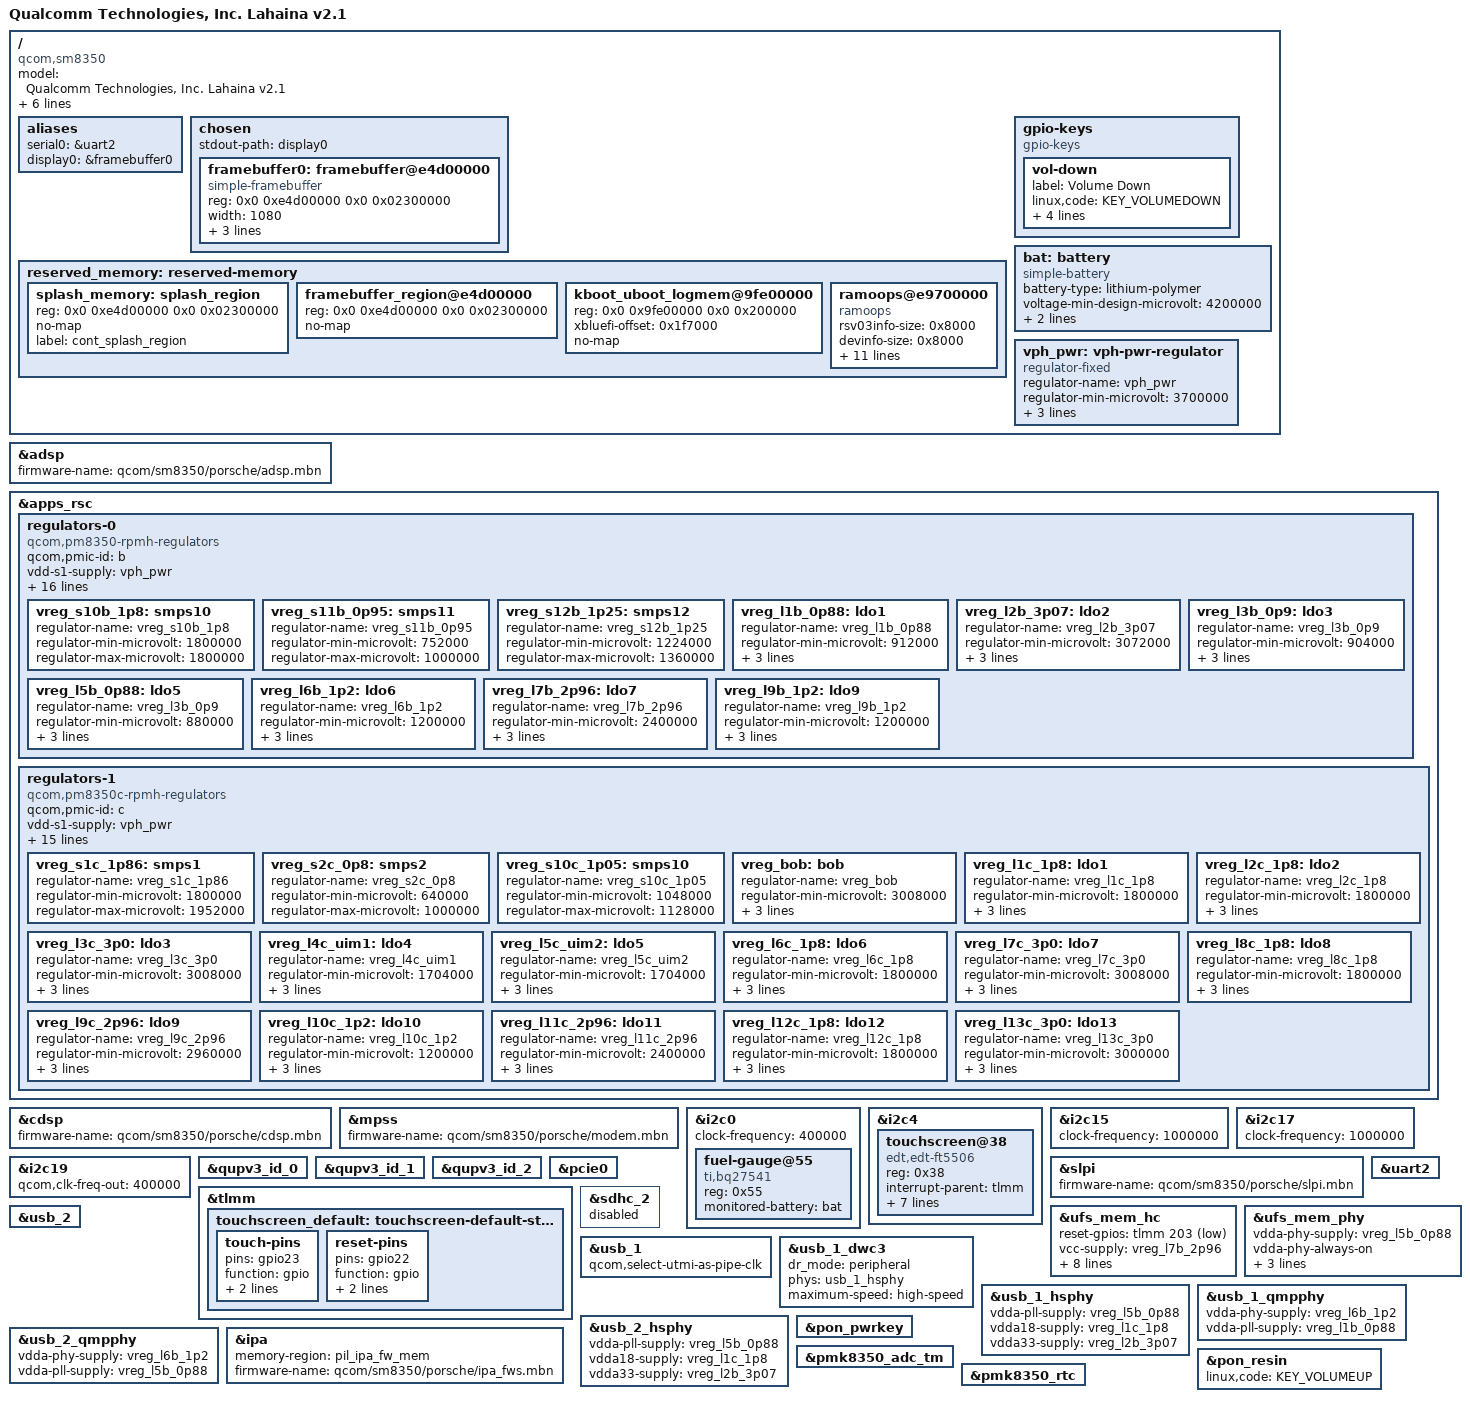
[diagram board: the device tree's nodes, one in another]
// SPDX-License-Identifier: BSD-3-Clause
/*
 * Copyright (c) 2023 Saikat Saha <ssaikatsaha1996@gmail.com>
 */

/dts-v1/;

#include <dt-bindings/pinctrl/qcom,pmic-gpio.h>
#include <dt-bindings/regulator/qcom,rpmh-regulator.h>
#include "sm8350.dtsi"
#include "pm8350.dtsi"
#include "pm8350b.dtsi"
#include "pm8350c.dtsi"
#include "pmk8350.dtsi"
#include "pmr735a.dtsi"
#include "pmr735b.dtsi"

/ {
	model = "Qualcomm Technologies, Inc. Lahaina v2.1";
        compatible = "qcom,sm8350", "qcom,lahaina";
        qcom,msm-id = <0x19f 0x20001 0x1c8 0x20001 0x1f5 0x20001>;
        qcom,board-id = <0 0>;
        oppo,dtsi_no = <0x5093>;

	interrupt-parent = <&intc>;

	#address-cells = <2>;
	#size-cells = <2>;

        chassis-type = "handset";

	aliases {
                serial0 = &uart2;
                //hsuart0 = &uart6;
		display0 = &framebuffer0;
	};

	chosen {
		#address-cells = <2>;
		#size-cells = <2>;
		ranges;
		stdout-path = "display0";

                framebuffer0: framebuffer@e4d00000 {
		        compatible = "simple-framebuffer";
		        reg = <0x0 0xe4d00000 0x0 0x02300000>;
		        width = <1080>;
		        height = <2400>;
		        stride = <(1080 * 4)>;
		        format = "a8r8g8b8";
                        status = "okay";
                };
	};

        reserved_memory: reserved-memory {
		#address-cells = <2>;
		#size-cells = <2>;
		ranges;

                splash_memory:splash_region {
                        reg = <0x0 0xe4d00000 0x0 0x02300000>;
                        no-map;
                        label = "cont_splash_region";
                };

                framebuffer_region@e4d00000 {
                        reg = <0x0 0xe4d00000 0x0 0x02300000>;
                        no-map;
                };

                kboot_uboot_logmem@9fe00000 {
                        reg = <0x0 0x9fe00000 0x0 0x200000>;
			xbluefi-offset = <0x1f7000>;
			no-map;
		};

                ramoops@e9700000 {
                        rsv03info-size = <0x8000>;
			devinfo-size = <0x8000>;
			ecc-size = <0x00>;
			rsv04info-size = <0x8000>;
			record-size = <0x40000>;
			rsv05info-size = <0x8000>;
			pmsg-size = <0x200000>;
			dumpinfo-size = <0x8000>;
			rsv01info-size = <0x8000>;
			compatible = "ramoops";
			console-size = <0x40000>;
			reg = <0x00 0xe9700000 0x00 0x5b8000>;
			phandle = <0x6f6>;
			rsv02info-size = <0x8000>;
			ftrace-size = <0x200000>;
                };


        };

        gpio-keys {
		compatible = "gpio-keys";

		vol-down {
			label = "Volume Down";
			linux,code = <KEY_VOLUMEDOWN>;
			gpios = <&pm8350_gpios 6 GPIO_ACTIVE_LOW>;
			debounce-interval = <15>;
			linux,can-disable;
			gpio-key,wakeup;
		};
	};

        bat: battery {
                compatible = "simple-battery";
                battery-type = "lithium-polymer";
                voltage-min-design-microvolt = <4200000>;
                energy-full-design-microwatt-hours = <23000000>;
                charge-full-design-microamp-hours = <5000000>;
        };

	vph_pwr: vph-pwr-regulator {
		compatible = "regulator-fixed";
		regulator-name = "vph_pwr";
		regulator-min-microvolt = <3700000>;
		regulator-max-microvolt = <3700000>;

		regulator-always-on;
		regulator-boot-on;
	};

};

&adsp {
	status = "okay";
	firmware-name = "qcom/sm8350/porsche/adsp.mbn";
};

&apps_rsc {
	regulators-0 {
		compatible = "qcom,pm8350-rpmh-regulators";
		qcom,pmic-id = "b";

		vdd-s1-supply = <&vph_pwr>;
		vdd-s2-supply = <&vph_pwr>;
		vdd-s3-supply = <&vph_pwr>;
		vdd-s4-supply = <&vph_pwr>;
		vdd-s5-supply = <&vph_pwr>;
		vdd-s6-supply = <&vph_pwr>;
		vdd-s7-supply = <&vph_pwr>;
		vdd-s8-supply = <&vph_pwr>;
		vdd-s9-supply = <&vph_pwr>;
		vdd-s10-supply = <&vph_pwr>;
		vdd-s11-supply = <&vph_pwr>;
		vdd-s12-supply = <&vph_pwr>;

		vdd-l1-l4-supply = <&vreg_s11b_0p95>;
		vdd-l2-l7-supply = <&vreg_bob>;
		vdd-l3-l5-supply = <&vreg_bob>;
		vdd-l6-l9-l10-supply = <&vreg_s11b_0p95>;
		vdd-l8-supply = <&vreg_s2c_0p8>;

		vreg_s10b_1p8: smps10 {
			regulator-name = "vreg_s10b_1p8";
			regulator-min-microvolt = <1800000>;
			regulator-max-microvolt = <1800000>;
		};

		vreg_s11b_0p95: smps11 {
			regulator-name = "vreg_s11b_0p95";
			regulator-min-microvolt = <752000>;
			regulator-max-microvolt = <1000000>;
		};

		vreg_s12b_1p25: smps12 {
			regulator-name = "vreg_s12b_1p25";
			regulator-min-microvolt = <1224000>;
			regulator-max-microvolt = <1360000>;
		};

		vreg_l1b_0p88: ldo1 {
			regulator-name = "vreg_l1b_0p88";
			regulator-min-microvolt = <912000>;
			regulator-max-microvolt = <920000>;
			regulator-initial-mode = <RPMH_REGULATOR_MODE_HPM>;
		};

		vreg_l2b_3p07: ldo2 {
			regulator-name = "vreg_l2b_3p07";
			regulator-min-microvolt = <3072000>;
			regulator-max-microvolt = <3072000>;
			regulator-initial-mode = <RPMH_REGULATOR_MODE_HPM>;
		};

		vreg_l3b_0p9: ldo3 {
			regulator-name = "vreg_l3b_0p9";
			regulator-min-microvolt = <904000>;
			regulator-max-microvolt = <904000>;
			regulator-initial-mode = <RPMH_REGULATOR_MODE_HPM>;
		};

		vreg_l5b_0p88: ldo5 {
			regulator-name = "vreg_l3b_0p9";
			regulator-min-microvolt = <880000>;
			regulator-max-microvolt = <888000>;
			regulator-initial-mode = <RPMH_REGULATOR_MODE_HPM>;
		};

		vreg_l6b_1p2: ldo6 {
			regulator-name = "vreg_l6b_1p2";
			regulator-min-microvolt = <1200000>;
			regulator-max-microvolt = <1208000>;
			regulator-initial-mode = <RPMH_REGULATOR_MODE_HPM>;
		};

		vreg_l7b_2p96: ldo7 {
			regulator-name = "vreg_l7b_2p96";
			regulator-min-microvolt = <2400000>;
			regulator-max-microvolt = <3008000>;
			regulator-initial-mode = <RPMH_REGULATOR_MODE_HPM>;
		};

		vreg_l9b_1p2: ldo9 {
			regulator-name = "vreg_l9b_1p2";
			regulator-min-microvolt = <1200000>;
			regulator-max-microvolt = <1200000>;
			regulator-initial-mode = <RPMH_REGULATOR_MODE_HPM>;
		};
	};

	regulators-1 {
		compatible = "qcom,pm8350c-rpmh-regulators";
		qcom,pmic-id = "c";

		vdd-s1-supply = <&vph_pwr>;
		vdd-s2-supply = <&vph_pwr>;
		vdd-s3-supply = <&vph_pwr>;
		vdd-s4-supply = <&vph_pwr>;
		vdd-s5-supply = <&vph_pwr>;
		vdd-s6-supply = <&vph_pwr>;
		vdd-s7-supply = <&vph_pwr>;
		vdd-s8-supply = <&vph_pwr>;
		vdd-s9-supply = <&vph_pwr>;
		vdd-s10-supply = <&vph_pwr>;

		vdd-l1-l12-supply = <&vreg_s1c_1p86>;
		vdd-l2-l8-supply = <&vreg_s1c_1p86>;
		vdd-l3-l4-l5-l7-l13-supply = <&vreg_bob>;
		vdd-l6-l9-l11-supply = <&vreg_bob>;
		vdd-l10-supply = <&vreg_s12b_1p25>;

		vdd-bob-supply = <&vph_pwr>;

		vreg_s1c_1p86: smps1 {
			regulator-name = "vreg_s1c_1p86";
			regulator-min-microvolt = <1800000>;
			regulator-max-microvolt = <1952000>;
		};

		vreg_s2c_0p8: smps2 {
			regulator-name = "vreg_s2c_0p8";
			regulator-min-microvolt = <640000>;
			regulator-max-microvolt = <1000000>;
		};

		vreg_s10c_1p05: smps10 {
			regulator-name = "vreg_s10c_1p05";
			regulator-min-microvolt = <1048000>;
			regulator-max-microvolt = <1128000>;
		};

		vreg_bob: bob {
			regulator-name = "vreg_bob";
			regulator-min-microvolt = <3008000>;
			regulator-max-microvolt = <3960000>;
			regulator-initial-mode = <RPMH_REGULATOR_MODE_AUTO>;
		};

		vreg_l1c_1p8: ldo1 {
			regulator-name = "vreg_l1c_1p8";
			regulator-min-microvolt = <1800000>;
			regulator-max-microvolt = <1800000>;
			regulator-initial-mode = <RPMH_REGULATOR_MODE_HPM>;
		};

		vreg_l2c_1p8: ldo2 {
			regulator-name = "vreg_l2c_1p8";
			regulator-min-microvolt = <1800000>;
			regulator-max-microvolt = <1800000>;
			regulator-initial-mode = <RPMH_REGULATOR_MODE_HPM>;
		};

		vreg_l3c_3p0: ldo3 {
			regulator-name = "vreg_l3c_3p0";
			regulator-min-microvolt = <3008000>;
			regulator-max-microvolt = <3008000>;
			regulator-initial-mode = <RPMH_REGULATOR_MODE_HPM>;
		};

		vreg_l4c_uim1: ldo4 {
			regulator-name = "vreg_l4c_uim1";
			regulator-min-microvolt = <1704000>;
			regulator-max-microvolt = <3000000>;
			regulator-initial-mode = <RPMH_REGULATOR_MODE_HPM>;
		};

		vreg_l5c_uim2: ldo5 {
			regulator-name = "vreg_l5c_uim2";
			regulator-min-microvolt = <1704000>;
			regulator-max-microvolt = <3000000>;
			regulator-initial-mode = <RPMH_REGULATOR_MODE_HPM>;
		};

		vreg_l6c_1p8: ldo6 {
			regulator-name = "vreg_l6c_1p8";
			regulator-min-microvolt = <1800000>;
			regulator-max-microvolt = <2960000>;
			regulator-initial-mode = <RPMH_REGULATOR_MODE_HPM>;
		};

		vreg_l7c_3p0: ldo7 {
			regulator-name = "vreg_l7c_3p0";
			regulator-min-microvolt = <3008000>;
			regulator-max-microvolt = <3008000>;
			regulator-initial-mode = <RPMH_REGULATOR_MODE_HPM>;
		};

		vreg_l8c_1p8: ldo8 {
			regulator-name = "vreg_l8c_1p8";
			regulator-min-microvolt = <1800000>;
			regulator-max-microvolt = <1800000>;
			regulator-initial-mode = <RPMH_REGULATOR_MODE_HPM>;
		};

		vreg_l9c_2p96: ldo9 {
			regulator-name = "vreg_l9c_2p96";
			regulator-min-microvolt = <2960000>;
			regulator-max-microvolt = <3008000>;
			regulator-initial-mode = <RPMH_REGULATOR_MODE_HPM>;
		};

		vreg_l10c_1p2: ldo10 {
			regulator-name = "vreg_l10c_1p2";
			regulator-min-microvolt = <1200000>;
			regulator-max-microvolt = <1200000>;
			regulator-initial-mode = <RPMH_REGULATOR_MODE_HPM>;
		};

		vreg_l11c_2p96: ldo11 {
			regulator-name = "vreg_l11c_2p96";
			regulator-min-microvolt = <2400000>;
			regulator-max-microvolt = <3008000>;
			regulator-initial-mode = <RPMH_REGULATOR_MODE_HPM>;
		};

		vreg_l12c_1p8: ldo12 {
			regulator-name = "vreg_l12c_1p8";
			regulator-min-microvolt = <1800000>;
			regulator-max-microvolt = <2000000>;
			regulator-initial-mode = <RPMH_REGULATOR_MODE_HPM>;
		};

		vreg_l13c_3p0: ldo13 {
			regulator-name = "vreg_l13c_3p0";
			regulator-min-microvolt = <3000000>;
			regulator-max-microvolt = <3000000>;
			regulator-initial-mode = <RPMH_REGULATOR_MODE_HPM>;
		};
        };
};

&cdsp {
	status = "okay";
	firmware-name = "qcom/sm8350/porsche/cdsp.mbn";
};

&mpss {
	status = "okay";
	firmware-name = "qcom/sm8350/porsche/modem.mbn";
};

&i2c0 {
	clock-frequency = <400000>;
	status = "okay";

	fuel-gauge@55 {
		compatible = "ti,bq27541";
		reg = <0x55>;
		monitored-battery = <&bat>;
	};
};

&i2c4 {
        status = "okay";
        #address-cells = <1>;
        #size-cells = <0>;
        touchscreen@38 {
                compatible = "edt,edt-ft5506";
                reg = <0x38>;
                interrupt-parent = <&tlmm>;
                interrupts = <23 IRQ_TYPE_EDGE_FALLING>;
                reset-gpio = <&tlmm 22 GPIO_ACTIVE_LOW>;

                vcc-supply = <&vreg_l11c_2p96>;
		iovcc-supply = <&vreg_l12c_1p8>;
                touchscreen-size-x = <1080>;
                touchscreen-size-y = <2400>;

                pinctrl-names = "default";
		pinctrl-0 = <&touchscreen_default>;
	};
};

&i2c15 {
        status = "okay";
        clock-frequency = <1000000>;

        /* NXP SN1X0 NFC @ 28 */
};

&i2c17 {
        status = "okay";
        clock-frequency = <1000000>;

        /* Cirrus Logic CS40L25A boosted haptics driver @ 40 */
};



&i2c19 {
       status ="okay";
       qcom,clk-freq-out = <400000>;
};


&qupv3_id_0 {
	status = "okay";
};

&qupv3_id_1 {
	status = "okay";
};

&qupv3_id_2 {
	status = "okay";
};

&slpi {
	status = "okay";
	firmware-name = "qcom/sm8350/porsche/slpi.mbn";
};

&pcie0 {
	status = "okay";
};

&tlmm {
        touchscreen_default: touchscreen-default-state {
		touch-pins {
			pins = "gpio23";
			function = "gpio";

			drive-strength = <2>;
			bias-pull-up;
		};

		reset-pins {
			pins = "gpio22";
			function = "gpio";

			drive-strength = <2>;
			bias-disable;
		};
	};
};

&uart2 {
        status = "okay";
};

&sdhc_2 {
	status = "disabled";
};

&ufs_mem_hc {
	status = "okay";

	reset-gpios = <&tlmm 203 GPIO_ACTIVE_LOW>;

	vcc-supply = <&vreg_l7b_2p96>;
	vcc-voltage-level = <2504000 2950000>;
	vcc-max-microamp = <800000>;
	vccq-supply = <&vreg_l9b_1p2>;
	vccq-max-microamp = <900000>;

	qcom,vddp-ref-clk-supply = <&vreg_l9b_1p2>;
	qcom,vddp-ref-clk-max-microamp = <100>;

	qcom,vccq-parent-supply = <&vreg_s12b_1p25>;
	qcom,vccq-parent-max-microamp = <210000>;
};

&ufs_mem_phy {
	status = "okay";

	vdda-phy-supply = <&vreg_l5b_0p88>;
	vdda-phy-always-on;
	vdda-max-microamp = <91600>;
	vdda-pll-supply = <&vreg_l6b_1p2>;
	vdda-pll-max-microamp = <19000>;
};

&usb_1 {
        status = "okay";
        qcom,select-utmi-as-pipe-clk;
};

&usb_1_dwc3 {
        dr_mode = "peripheral";
        phys = <&usb_1_hsphy>;
        phy-names = "usb2-phy";
        maximum-speed = "high-speed";
};

&usb_1_hsphy {
	status = "okay";

	vdda-pll-supply = <&vreg_l5b_0p88>;
	vdda18-supply = <&vreg_l1c_1p8>;
	vdda33-supply = <&vreg_l2b_3p07>;
};

&usb_1_qmpphy {
	status = "okay";

	vdda-phy-supply = <&vreg_l6b_1p2>;
	vdda-pll-supply = <&vreg_l1b_0p88>;
};

&usb_2 {
	status = "okay";
};

&usb_2_hsphy {
	status = "okay";

	vdda-pll-supply = <&vreg_l5b_0p88>;
	vdda18-supply = <&vreg_l1c_1p8>;
	vdda33-supply = <&vreg_l2b_3p07>;
};

&usb_2_qmpphy {
	status = "okay";

	vdda-phy-supply = <&vreg_l6b_1p2>;
	vdda-pll-supply = <&vreg_l5b_0p88>;
};

&ipa {
	status = "okay";

	memory-region = <&pil_ipa_fw_mem>;
	firmware-name = "qcom/sm8350/porsche/ipa_fws.mbn";
};

&pon_resin {
	status = "okay";
	linux,code = <KEY_VOLUMEUP>;
};

&pon_pwrkey {
	status = "okay";
};

&pmk8350_adc_tm {
	status = "okay";
};

&pmk8350_rtc {
	status = "okay";
};
